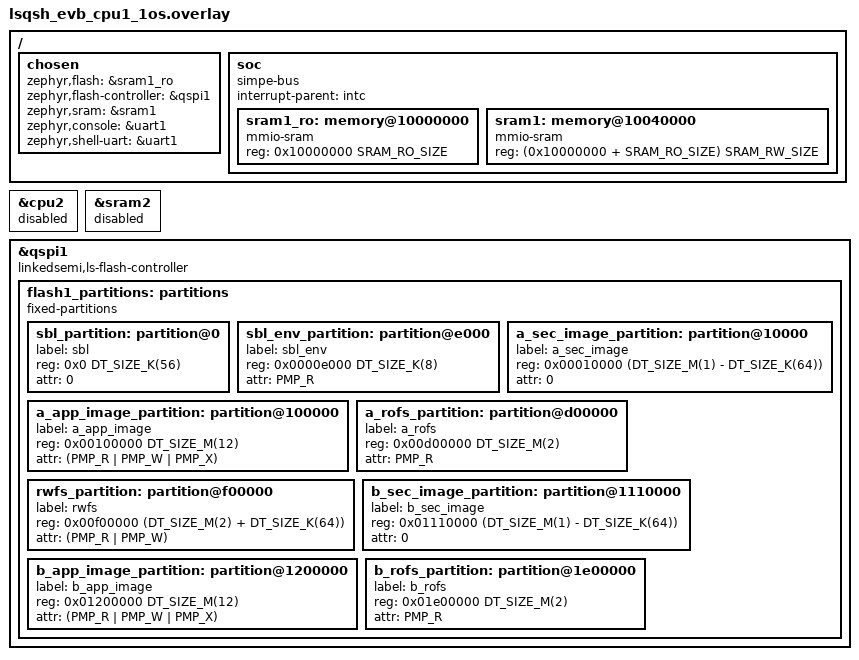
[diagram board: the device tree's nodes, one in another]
/*
 * Copyright (c) 2025 linkedsemi
 * SPDX-License-Identifier: Apache-2.0
 */

#include "lsqsh_evb_pinctrl.dtsi"

#undef SRAM_TOTAL_SIZE
#define SRAM_TOTAL_SIZE DT_SIZE_K(512 + 760)

#undef SRAM_RO_SIZE
#define SRAM_RO_SIZE    DT_SIZE_K(512)

#undef SRAM_RW_SIZE
#define SRAM_RW_SIZE    (SRAM_TOTAL_SIZE - SRAM_RO_SIZE)

/ {
    chosen {
        zephyr,flash = &sram1_ro;
        zephyr,flash-controller = &qspi1;
        zephyr,sram = &sram1;
        zephyr,console = &uart1;
        zephyr,shell-uart = &uart1;
    };

    soc {
        compatible = "simpe-bus";
        #address-cells = <1>;
        #size-cells = <1>;
        interrupt-parent = <&intc>;

        /delete-node/ memory@10000000;
        sram1_ro: memory@10000000 {
            compatible = "mmio-sram";
            reg = <0x10000000 SRAM_RO_SIZE>;
        };

        sram1: memory@10040000 {
            compatible = "mmio-sram";
            reg = <(0x10000000 + SRAM_RO_SIZE) SRAM_RW_SIZE>;
        };
    };
};

&cpu2 {
    status = "disabled";
};

&sram2 {
    status = "disabled";
};

&qspi1 {
    compatible = "linkedsemi,ls-flash-controller";
    status = "okay";
};

&qspi1 {
    flash1_partitions: partitions {
        compatible = "fixed-partitions";
        #address-cells = <1>;
        #size-cells = <1>;

        /* sbl */
        sbl_partition: partition@0 {
            label = "sbl";
            reg = <0x0 DT_SIZE_K(56)>;
            attr = <0>;
        };
        sbl_env_partition: partition@e000 {
            label = "sbl_env";
            reg = <0x0000e000 DT_SIZE_K(8)>;
            attr = <PMP_R>;
        };

        /* a */
        a_sec_image_partition: partition@10000 {
            label = "a_sec_image";
            reg = <0x00010000 (DT_SIZE_M(1) - DT_SIZE_K(64))>;
            attr = <0>;
        };
        a_app_image_partition: partition@100000 {
            label = "a_app_image";
            reg = <0x00100000 DT_SIZE_M(12)>;
            attr = <(PMP_R | PMP_W | PMP_X)>;
        };
        a_rofs_partition: partition@d00000 {
            label = "a_rofs";
            reg = <0x00d00000 DT_SIZE_M(2)>;
            attr = <PMP_R>;
        };

        /* common */
        rwfs_partition: partition@f00000 {
            label = "rwfs";
            reg = <0x00f00000 (DT_SIZE_M(2) + DT_SIZE_K(64))>;
            attr = <(PMP_R | PMP_W)>;
        };

        /* b */
        b_sec_image_partition: partition@1110000 {
            label = "b_sec_image";
            reg = <0x01110000 (DT_SIZE_M(1) - DT_SIZE_K(64))>;
            attr = <0>;
        };
        b_app_image_partition: partition@1200000 {
            label = "b_app_image";
            reg = <0x01200000 DT_SIZE_M(12)>;
            attr = <(PMP_R | PMP_W | PMP_X)>;
        };
        b_rofs_partition: partition@1e00000 {
            label = "b_rofs";
            reg = <0x01e00000 DT_SIZE_M(2)>;
            attr = <PMP_R>;
        };
    };
};
